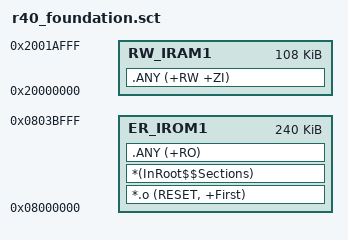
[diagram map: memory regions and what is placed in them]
; R40底层验证镜像：从内部Flash起点独立启动，使用芯片完整RAM范围。
; 末16KiB参数区不得被程序占用；完整APP身份和Loader布局后续单独冻结。
LR_IROM1 0x08000000 0x0003C000 {
  ER_IROM1 0x08000000 0x0003C000 {
    *.o (RESET, +First)
    *(InRoot$$Sections)
    .ANY (+RO)
  }
  RW_IRAM1 0x20000000 0x0001B000 {
    .ANY (+RW +ZI)
  }
}
